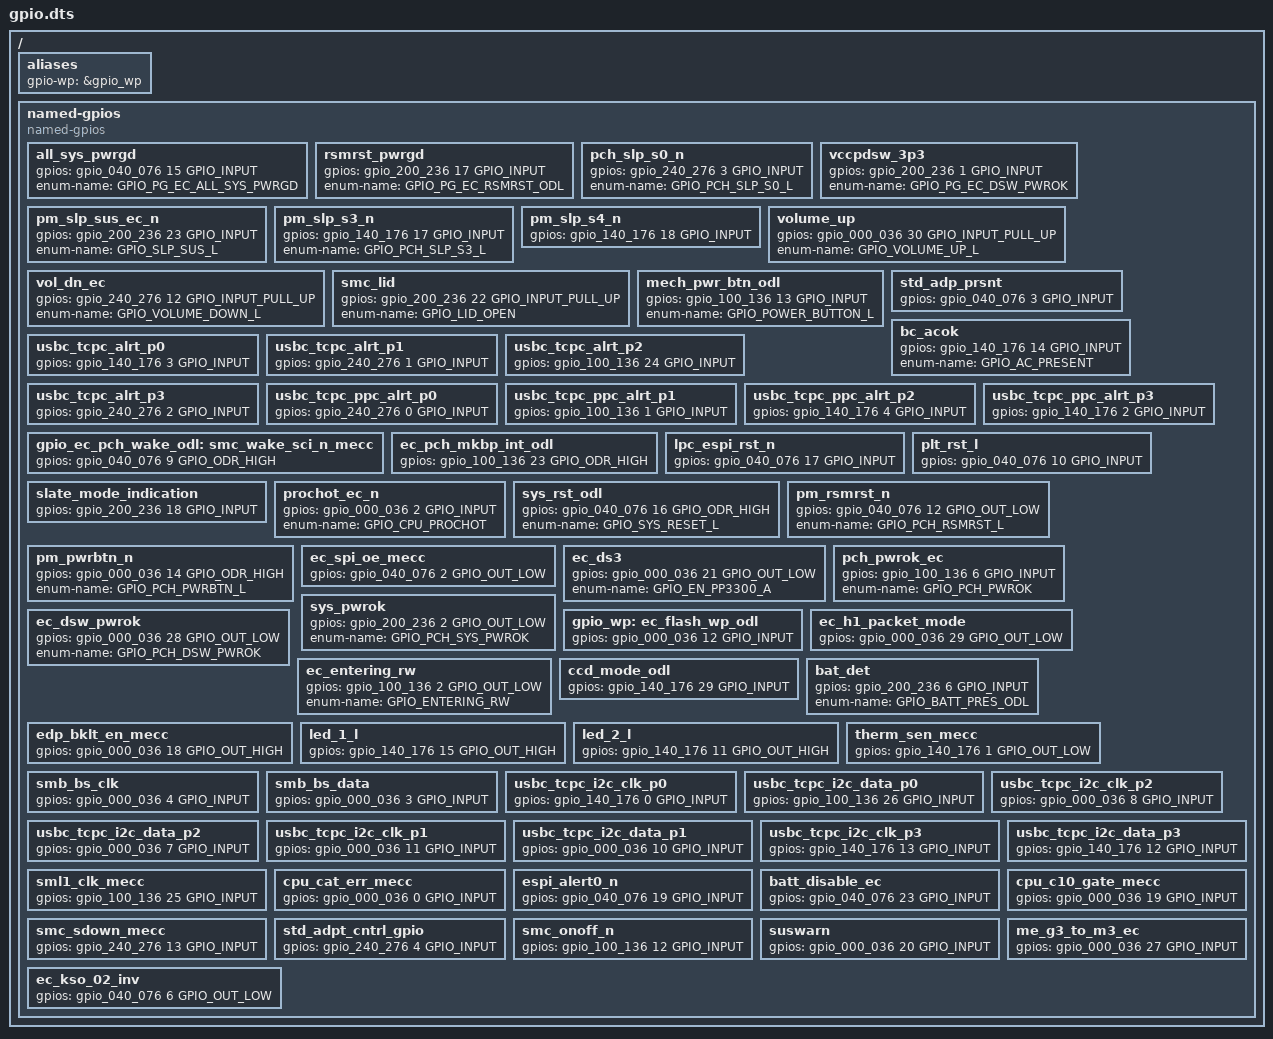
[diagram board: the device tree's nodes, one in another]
/* Copyright 2022 The Chromium OS Authors. All rights reserved.
 * Use of this source code is governed by a BSD-style license that can be
 * found in the LICENSE file.
 */

/ {

	aliases {
		gpio-wp = &gpio_wp;
		/* gpio-kbd-kso2 = &gpio_ec_kso_02_inv; */
	};

	named-gpios {
		compatible = "named-gpios";

		all_sys_pwrgd: all_sys_pwrgd {
			gpios = <&gpio_040_076 15 GPIO_INPUT>;
			enum-name = "GPIO_PG_EC_ALL_SYS_PWRGD";
		}; /* GPIO057 */
		rsmrst_pwrgd: rsmrst_pwrgd {
			gpios = <&gpio_200_236 17 GPIO_INPUT>;
			enum-name = "GPIO_PG_EC_RSMRST_ODL";
		}; /* GPIO221 */
		pch_slp_s0_n: pch_slp_s0_n {
			gpios = <&gpio_240_276 3 GPIO_INPUT>;
			enum-name = "GPIO_PCH_SLP_S0_L";
		}; /* GPIO243 */
		vccpdsw_3p3: vccpdsw_3p3 {
			gpios = <&gpio_200_236 1 GPIO_INPUT>;
			enum-name = "GPIO_PG_EC_DSW_PWROK";
		}; /* GPIO201 */
		pm_slp_sus_ec_n: pm_slp_sus_ec_n {
			gpios = <&gpio_200_236 23 GPIO_INPUT>;
			enum-name = "GPIO_SLP_SUS_L";
		}; /* GPIO227 */
		pm_slp_s3_n: pm_slp_s3_n {
			gpios = <&gpio_140_176 17 GPIO_INPUT>;
			enum-name = "GPIO_PCH_SLP_S3_L";
		}; /* GPIO161 */
		pm_slp_s4_n: pm_slp_s4_n {
			gpios = <&gpio_140_176 18 GPIO_INPUT>;
		}; /* GPIO162 */
		volume_up {
			gpios = <&gpio_000_036 30 GPIO_INPUT_PULL_UP>;
			enum-name = "GPIO_VOLUME_UP_L";
		}; /* GPIO036 */
		vol_dn_ec {
			gpios = <&gpio_240_276 12 GPIO_INPUT_PULL_UP>;
			enum-name = "GPIO_VOLUME_DOWN_L";
		}; /* GPIO254 */
		smc_lid: smc_lid {
			gpios = <&gpio_200_236 22 GPIO_INPUT_PULL_UP>;
			enum-name = "GPIO_LID_OPEN";
		}; /* GPIO226 */
		mech_pwr_btn_odl: mech_pwr_btn_odl {
			gpios = <&gpio_100_136 13 GPIO_INPUT>;
			enum-name = "GPIO_POWER_BUTTON_L";
		}; /* GPIO115 */
		std_adp_prsnt {
			gpios = <&gpio_040_076 3 GPIO_INPUT>;
		}; /* GPIO043 */
		bc_acok: bc_acok {
			gpios = <&gpio_140_176 14 GPIO_INPUT>;
			enum-name = "GPIO_AC_PRESENT";
		}; /* GPIO156 */
		usbc_tcpc_alrt_p0 {
			gpios = <&gpio_140_176 3 GPIO_INPUT>;
		}; /* GPIO143 */
		usbc_tcpc_alrt_p1 {
			gpios = <&gpio_240_276 1 GPIO_INPUT>;
		}; /* GPIO241 */
		usbc_tcpc_alrt_p2 {
			gpios = <&gpio_100_136 24 GPIO_INPUT>;
		}; /* GPIO130 */
		usbc_tcpc_alrt_p3 {
			gpios = <&gpio_240_276 2 GPIO_INPUT>;
		}; /* GPIO242 */
		usbc_tcpc_ppc_alrt_p0 {
			gpios = <&gpio_240_276 0 GPIO_INPUT>;
		}; /* GPIO240 */
		usbc_tcpc_ppc_alrt_p1 {
			gpios = <&gpio_100_136 1 GPIO_INPUT>;
		}; /* GPIO101 */
		usbc_tcpc_ppc_alrt_p2 {
			gpios = <&gpio_140_176 4 GPIO_INPUT>;
		}; /* GPIO144 */
		usbc_tcpc_ppc_alrt_p3 {
			gpios = <&gpio_140_176 2 GPIO_INPUT>;
		}; /* GPIO142 */
		gpio_ec_pch_wake_odl: smc_wake_sci_n_mecc {
			gpios = <&gpio_040_076 9 GPIO_ODR_HIGH>;
			/* enum-name = "GPIO_EC_PCH_WAKE_ODL"; */
		}; /* GPIO051 */
		ec_pch_mkbp_int_odl {
			gpios = <&gpio_100_136 23 GPIO_ODR_HIGH>;
		}; /* GPIO127 */
		lpc_espi_rst_n {
			gpios = <&gpio_040_076 17 GPIO_INPUT>;
		}; /* GPIO061 NANA */
		plt_rst_l {
			gpios = <&gpio_040_076 10 GPIO_INPUT>;
		}; /* GPIO052 NANA */
		slate_mode_indication {
			gpios = <&gpio_200_236 18 GPIO_INPUT>;
		}; /* GPIO222 */
		prochot_ec_n {
			gpios = <&gpio_000_036 2 GPIO_INPUT>;
			enum-name = "GPIO_CPU_PROCHOT";
		}; /* GPIO002 ???? */
		sys_rst_odl {
			gpios = <&gpio_040_076 16 GPIO_ODR_HIGH>;
			/* enum-name = "GPIO_SYS_RST_ODL"; */
			enum-name = "GPIO_SYS_RESET_L";
		}; /* GPIO060 */
		pm_rsmrst_n {
			gpios = <&gpio_040_076 12 GPIO_OUT_LOW>;
			enum-name = "GPIO_PCH_RSMRST_L";
		}; /* GPIO054 */
		pm_pwrbtn_n {
			gpios = <&gpio_000_036 14 GPIO_ODR_HIGH>;
			enum-name = "GPIO_PCH_PWRBTN_L";
		}; /* GPIO016 */
		ec_spi_oe_mecc: ec_spi_oe_mecc {
			gpios = <&gpio_040_076 2 GPIO_OUT_LOW>;
		}; /* GPIO042 */
		ec_ds3 {
			gpios = <&gpio_000_036 21 GPIO_OUT_LOW>;
			enum-name = "GPIO_EN_PP3300_A";
		}; /* GPIO025 */
		pch_pwrok_ec {
			gpios = <&gpio_100_136 6 GPIO_INPUT>;
			enum-name = "GPIO_PCH_PWROK";
		}; /* GPIO106 */
		sys_pwrok {
			gpios = <&gpio_200_236 2 GPIO_OUT_LOW>;
			/* enum-name = "GPIO_EC_PCH_SYS_PWROK"; */
			enum-name = "GPIO_PCH_SYS_PWROK";
		}; /* GPIO202 */
		ec_dsw_pwrok {
			gpios = <&gpio_000_036 28 GPIO_OUT_LOW>;
			enum-name = "GPIO_PCH_DSW_PWROK";
		}; /* GPIO034 */
		gpio_wp: ec_flash_wp_odl {
			gpios = <&gpio_000_036 12 GPIO_INPUT>;
			/* enum-name = "GPIO_WP_L"; */
		}; /* GPIO014 */
		ec_h1_packet_mode {
			gpios = <&gpio_000_036 29 GPIO_OUT_LOW>;
		}; /* GPIO035 */
		ec_entering_rw {
			gpios = <&gpio_100_136 2 GPIO_OUT_LOW>;
			enum-name = "GPIO_ENTERING_RW";
		}; /* GPIO102 */
		ccd_mode_odl {
			gpios = <&gpio_140_176 29 GPIO_INPUT>;
		}; /* GPIO175 */
		bat_det {
			gpios = <&gpio_200_236 6 GPIO_INPUT>;
			enum-name = "GPIO_BATT_PRES_ODL";
		}; /* GPIO206 */
		edp_bklt_en_mecc {
			gpios = <&gpio_000_036 18 GPIO_OUT_HIGH>;
		}; /* GPIO022 */
		led_1_l {
			gpios = <&gpio_140_176 15 GPIO_OUT_HIGH>;
		}; /* GPIO157 */
		led_2_l {
			gpios = <&gpio_140_176 11 GPIO_OUT_HIGH>;
		}; /* GPIO153 */
		therm_sen_mecc {
			gpios = <&gpio_140_176 1 GPIO_OUT_LOW>;
		}; /* GPIO141 */
		smb_bs_clk {
			gpios = <&gpio_000_036 4 GPIO_INPUT>;
		}; /* GPIO004 */
		smb_bs_data {
			gpios = <&gpio_000_036 3 GPIO_INPUT>;
		}; /* GPIO003 */
		usbc_tcpc_i2c_clk_p0 {
			gpios = <&gpio_140_176 0 GPIO_INPUT>;
		}; /* GPIO140 */
		usbc_tcpc_i2c_data_p0 {
			gpios = <&gpio_100_136 26 GPIO_INPUT>;
		}; /* GPIO132 */
		usbc_tcpc_i2c_clk_p2 {
			gpios = <&gpio_000_036 8 GPIO_INPUT>;
		}; /* GPIO010 */
		usbc_tcpc_i2c_data_p2 {
			gpios = <&gpio_000_036 7 GPIO_INPUT>;
		}; /* GPIO007 */
		usbc_tcpc_i2c_clk_p1 {
			gpios = <&gpio_000_036 11 GPIO_INPUT>;
		}; /* GPIO013 */
		usbc_tcpc_i2c_data_p1 {
			gpios = <&gpio_000_036 10 GPIO_INPUT>;
		}; /* GPIO012 */
		usbc_tcpc_i2c_clk_p3 {
			gpios = <&gpio_140_176 13 GPIO_INPUT>;
		}; /* GPIO155 */
		usbc_tcpc_i2c_data_p3 {
			gpios = <&gpio_140_176 12 GPIO_INPUT>;
		}; /* GPIO154 */
		sml1_clk_mecc {
			gpios = <&gpio_100_136 25 GPIO_INPUT>;
		}; /* GPIO131 */
        /* sml1_data_mecc {
			gpios = <&gpio_040_076 15 GPIO_INPUT>;
		};
		smb_pch_clk {
			gpios = <&gpio_040_076 15 GPIO_INPUT>;
		};
		smb_pch_data {
			gpios = <&gpio_040_076 15 GPIO_INPUT>;
		};
		i3c_0_scl {
			gpios = <&gpio_040_076 15 GPIO_INPUT>;
		};
		i3c_0_sda {
			gpios = <&gpio_040_076 15 GPIO_INPUT>;
		}; NANA */
		cpu_cat_err_mecc {
			gpios = <&gpio_000_036 0 GPIO_INPUT>;
		}; /* GPIO000 */
		/* tp29 {
			gpios = <&gpio_040_076 15 GPIO_INPUT>;
		};
		tp28 {
			gpios = <&gpio_040_076 15 GPIO_INPUT>;
		}; NANA */
		espi_alert0_n {
			gpios = <&gpio_040_076 19 GPIO_INPUT>;
		}; /* GPIO063 NANA */
		batt_disable_ec {
			gpios = <&gpio_040_076 23 GPIO_INPUT>;
		}; /* GPIO067 */
		/* tp33 {
			gpios = <&gpio_040_076 15 GPIO_INPUT>;
		};
		tp26 {
			gpios = <&gpio_040_076 15 GPIO_INPUT>;
		};
		slp_s0_cs_n {
			gpios = <&gpio_040_076 15 GPIO_INPUT>;
		};
		ec_peci {
			gpios = <&gpio_040_076 15 GPIO_INPUT>;
		}; NANA */
		cpu_c10_gate_mecc {
			gpios = <&gpio_000_036 19 GPIO_INPUT>;
		}; /* GPIO023 */
		/* smb_pch_alrt {
			gpios = <&gpio_040_076 15 GPIO_INPUT>;
		}; NANA */
		smc_sdown_mecc {
			gpios = <&gpio_240_276 13 GPIO_INPUT>;
		}; /* GPIO255 */
		std_adpt_cntrl_gpio {
			gpios = <&gpio_240_276 4 GPIO_INPUT>;
		}; /* GPIO244 */
		/* sml1_alert {
			gpios = <&gpio_040_076 15 GPIO_INPUT>;
		}; NANA */
		smc_onoff_n {
			gpios = <&gpio_100_136 12 GPIO_INPUT>;
		}; /* GPIO114 */
		suswarn {
			gpios = <&gpio_000_036 20 GPIO_INPUT>;
		}; /* GPIO024 */
		/* tp_gpiod6_ec {
			gpios = <&gpio_040_076 15 GPIO_INPUT>;
		};
		tp_gpiod7_ec {
			gpios = <&gpio_040_076 15 GPIO_INPUT>;
		}; NANA */
		me_g3_to_m3_ec {
			gpios = <&gpio_000_036 27 GPIO_INPUT>;
		}; /* GPIO033 */
		ec_kso_02_inv {
			gpios = <&gpio_040_076 6 GPIO_OUT_LOW>;
			/* enum-name = "GPIO_KBD_KSO2"; */
		}; /* GPIO046 KBD_KSO2 ???? */
	};
};
